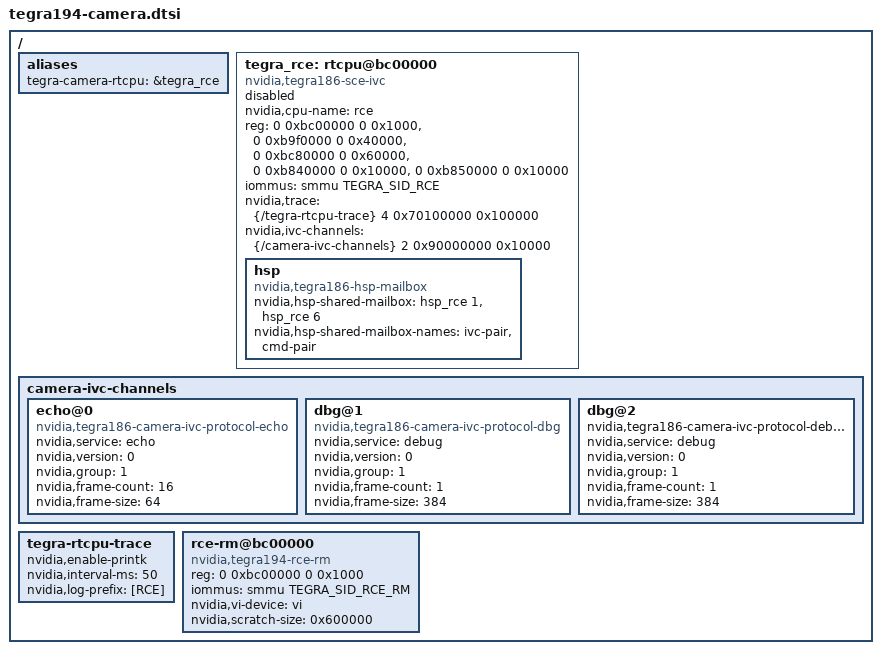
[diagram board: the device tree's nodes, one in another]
/*
 * tegra194-camera.dtsi: Camera RTCPU DTSI file.
 *
 * Copyright (c) 2016-2017, NVIDIA Corporation.  All rights reserved.
 *
 * This program is free software; you can redistribute it and/or modify
 * it under the terms of the GNU General Public License as published by
 * the Free Software Foundation; version 2 of the License.
 *
 * This program is distributed in the hope that it will be useful, but WITHOUT
 * ANY WARRANTY; without even the implied warranty of MERCHANTABILITY or
 * FITNESS FOR A PARTICULAR PURPOSE.  See the GNU General Public License for
 * more details.
 *
 * You should have received a copy of the GNU General Public License along
 * with this program; if not, write to the Free Software Foundation, Inc.,
 * 51 Franklin Street, Fifth Floor, Boston, MA  02110-1301, USA.
 *
 */

/ {
	aliases { /* RCE is the Camera RTCPU */
		tegra-camera-rtcpu = &tegra_rce;
	};

	tegra_rce: rtcpu@bc00000 {
		compatible = "nvidia,tegra186-sce-ivc";
		status = "disabled";

		nvidia,cpu-name = "rce";

		reg =	<0 0xbc00000 0 0x1000>,	  /* RCE EVP (RCE_ATCM_EVP) */
			<0 0xb9f0000 0 0x40000>,  /* RCE PM */
			<0 0xbc80000 0 0x60000>,  /* RCE BTCM */
			<0 0xb840000 0 0x10000>,
			<0 0xb850000 0 0x10000>;

		reg-names = "sce-evp", "sce-pm", "sce-fw",
				"ast-cpu", "ast-dma";

		iommus = <&smmu TEGRA_SID_RCE>;

		nvidia,trace = <&{/tegra-rtcpu-trace} 4 0x70100000 0x100000>;
		nvidia,ivc-channels = <&{/camera-ivc-channels} 2 0x90000000 0x10000>;

		hsp {
			compatible = "nvidia,tegra186-hsp-mailbox";
			nvidia,hsp-shared-mailbox = <&hsp_rce 1 &hsp_rce 6>;
			nvidia,hsp-shared-mailbox-names = "ivc-pair", "cmd-pair";
		};
	};

	camera-ivc-channels {
		#address-cells = <1>;
		#size-cells = <0>;

		echo@0 {
			compatible = "nvidia,tegra186-camera-ivc-protocol-echo";
			nvidia,service = "echo";
			nvidia,version = <0>;
			nvidia,group = <1>;
			nvidia,frame-count = <16>;
			nvidia,frame-size = <64>;
		};
		dbg@1 {
			/* This is raw channel exposed as device */
			compatible = "nvidia,tegra186-camera-ivc-protocol-dbg";
			nvidia,service = "debug";
			nvidia,version = <0>;
			nvidia,group = <1>;
			nvidia,frame-count = <1>;
			nvidia,frame-size = <384>;
		};
		dbg@2 {
			/* This is exposed in debugfs */
			compatible = "nvidia,tegra186-camera-ivc-protocol-debug";
			nvidia,service = "debug";
			nvidia,version = <0>;
			nvidia,group = <1>;
			nvidia,frame-count = <1>;
			nvidia,frame-size = <384>;
		};
	};

	tegra-rtcpu-trace {
		nvidia,enable-printk;
		nvidia,interval-ms = <50>;
		nvidia,log-prefix = "[RCE]";
	};

	rce-rm@bc00000 {
		compatible = "nvidia,tegra194-rce-rm";
		reg = <0 0xbc00000 0 0x1000>;

		iommus = <&smmu TEGRA_SID_RCE_RM>;

		nvidia,vi-device = <&vi>;

		nvidia,scratch-size = <0x600000>; /* 6M */
	};
};
